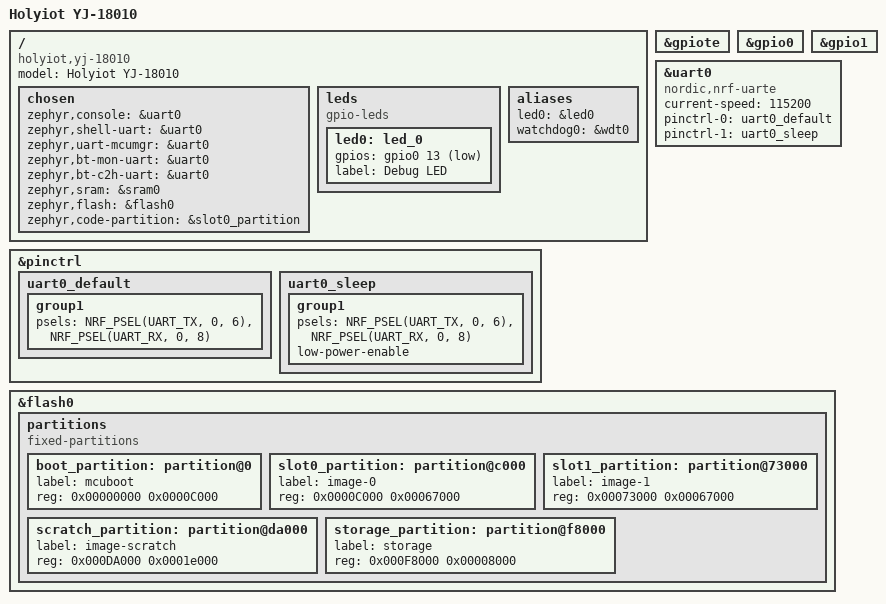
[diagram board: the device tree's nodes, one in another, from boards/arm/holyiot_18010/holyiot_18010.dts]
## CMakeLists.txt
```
# SPDX-License-Identifier: Apache-2.0
# Google FMDN Tracker Firmware (v3 - Dynamic EID)

cmake_minimum_required(VERSION 3.20.0)

# Add custom board definitions
list(APPEND BOARD_ROOT ${CMAKE_CURRENT_SOURCE_DIR})

find_package(Zephyr REQUIRED HINTS $ENV{ZEPHYR_BASE})

project(google_fmdn_tracker)

# Application sources
target_sources(app PRIVATE
    src/main.c
    src/eid_crypto.c
    src/gatt_service.c
)

# tiny-aes-c (AES-256-ECB, ~2 KB flash)
target_sources(app PRIVATE lib/tiny-aes/aes.c)
target_include_directories(app PRIVATE lib/tiny-aes)
target_compile_definitions(app PRIVATE AES256=1)

# micro-ecc (SECP160R1 point multiply, ~4-6 KB flash)
target_sources(app PRIVATE lib/micro-ecc/uECC.c)
target_include_directories(app PRIVATE lib/micro-ecc)
target_compile_definitions(app PRIVATE
    uECC_SUPPORTS_secp160r1=1
    uECC_SUPPORT_COMPRESSED_POINT=0
    uECC_OPTIMIZATION_LEVEL=2
)

target_include_directories(app PRIVATE
    include
    src
)
```

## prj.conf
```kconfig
# Google FMDN Tracker - Dynamic EID (v3)
# Supported: nRF52840, nRF52832
# v3: On-device EID computation + GATT activation window

# ============================================
# Bluetooth - Broadcaster + Peripheral (for GATT)
# ============================================
CONFIG_BT=y
CONFIG_BT_BROADCASTER=y
CONFIG_BT_PERIPHERAL=y

# GATT for activation window
CONFIG_BT_GATT_DYNAMIC_DB=y

# Disable unused features
CONFIG_BT_OBSERVER=n
CONFIG_BT_GATT_CLIENT=n
CONFIG_BT_SETTINGS=n

# ============================================
# Identity management for MAC rotation
# bt_id_reset() changes MAC on each slot rotation
# ============================================
CONFIG_BT_ID_MAX=2

# ============================================
# TX Power - +4 dBm (balanced range/power)
# ============================================
CONFIG_BT_CTLR_TX_PWR_PLUS_4=y

# ============================================
# USB CDC ACM Console (debug build)
# ============================================
CONFIG_SERIAL=y
CONFIG_CONSOLE=y
CONFIG_USB_DEVICE_STACK_NEXT=y
CONFIG_UART_CONSOLE=y
CONFIG_UART_LINE_CTRL=y

# ============================================
# Logging via USB console
# ============================================
CONFIG_LOG=y
CONFIG_LOG_DEFAULT_LEVEL=3
CONFIG_LOG_BACKEND_UART=y
CONFIG_LOG_MODE_DEFERRED=y

# ============================================
# Stack sizes (larger for EC point multiply at boot)
# ============================================
CONFIG_MAIN_STACK_SIZE=4096
CONFIG_SYSTEM_WORKQUEUE_STACK_SIZE=4096
CONFIG_BT_RX_STACK_SIZE=1200

# ============================================
# Size Optimization
# ============================================
CONFIG_SIZE_OPTIMIZATIONS=y
CONFIG_SPEED_OPTIMIZATIONS=n

# ============================================
# Enable MPU Stack Protection
# ============================================
CONFIG_HW_STACK_PROTECTION=y

# ============================================
# LIBC fix for nrf-sdk
# ============================================
CONFIG_MINIMAL_LIBC=y
CONFIG_PICOLIBC=n
```

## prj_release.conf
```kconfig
# Google FMDN Tracker - Ultra Low Power
# Supported: nRF52840, nRF52832
# Version 8: rotation fix (stack + retry + MAC rotation)

# ============================================
# Bluetooth - Minimal Broadcaster
# ============================================
CONFIG_BT=y
CONFIG_BT_BROADCASTER=y

# Disable unused features
CONFIG_BT_PERIPHERAL=n
CONFIG_BT_OBSERVER=n
CONFIG_BT_GATT_CLIENT=n
CONFIG_BT_SETTINGS=n

# ============================================
# Identity management for MAC rotation
# bt_id_reset() changes MAC on each entity rotation
# ============================================
CONFIG_BT_ID_MAX=2

# ============================================
# TX Power - +4 dBm (balanced range/power)
# ============================================
CONFIG_BT_CTLR_TX_PWR_PLUS_4=y

# ============================================
# Disable Serial/UART (saves ~1-5mA)
# ============================================
CONFIG_SERIAL=n
CONFIG_CONSOLE=n
CONFIG_UART_CONSOLE=n

# ============================================
# Disable Logging (saves CPU cycles)
# ============================================
CONFIG_LOG=n
# Note: PRINTK is a dependency of other modules, can't disable

# ============================================
# DC/DC Regulator - already enabled in DTS for nrf52840dk
# (regulator-initial-mode = NRF5X_REG_MODE_DCDC)
# ============================================

# ============================================
# Stack sizes (workqueue needs room for BLE ops during rotation)
# ============================================
CONFIG_MAIN_STACK_SIZE=1024
CONFIG_SYSTEM_WORKQUEUE_STACK_SIZE=2048
CONFIG_BT_RX_STACK_SIZE=1024

# ============================================
# Size Optimization
# ============================================
CONFIG_SIZE_OPTIMIZATIONS=y
CONFIG_SPEED_OPTIMIZATIONS=n

# ============================================
# Enable MPU Stack Protection (detects overflow instead of silent crash)
# ============================================
CONFIG_HW_STACK_PROTECTION=y

# ============================================
# LIBC fix for nrf-sdk
# ============================================
CONFIG_MINIMAL_LIBC=y
CONFIG_PICOLIBC=n
```

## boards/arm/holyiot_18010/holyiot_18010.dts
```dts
/*
 * Holyiot YJ-18010 - nRF52840 Module with Ceramic Antenna
 * Board definition for Zephyr RTOS
 */

/dts-v1/;
#include <nordic/nrf52840_qiaa.dtsi>

/ {
	model = "Holyiot YJ-18010";
	compatible = "holyiot,yj-18010";

	chosen {
		zephyr,console = &uart0;
		zephyr,shell-uart = &uart0;
		zephyr,uart-mcumgr = &uart0;
		zephyr,bt-mon-uart = &uart0;
		zephyr,bt-c2h-uart = &uart0;
		zephyr,sram = &sram0;
		zephyr,flash = &flash0;
		zephyr,code-partition = &slot0_partition;
	};

	/* Optional: LED for debugging (connect external if needed) */
	leds {
		compatible = "gpio-leds";
		led0: led_0 {
			gpios = <&gpio0 13 GPIO_ACTIVE_LOW>;
			label = "Debug LED";
		};
	};

	/* Aliases */
	aliases {
		led0 = &led0;
		watchdog0 = &wdt0;
	};
};

&gpiote {
	status = "okay";
};

&gpio0 {
	status = "okay";
};

&gpio1 {
	status = "okay";
};

/* UART for debugging (optional - can be disabled for production) */
&uart0 {
	compatible = "nordic,nrf-uarte";
	status = "okay";
	current-speed = <115200>;
	pinctrl-0 = <&uart0_default>;
	pinctrl-1 = <&uart0_sleep>;
	pinctrl-names = "default", "sleep";
};

&pinctrl {
	uart0_default: uart0_default {
		group1 {
			psels = <NRF_PSEL(UART_TX, 0, 6)>,
			        <NRF_PSEL(UART_RX, 0, 8)>;
		};
	};

	uart0_sleep: uart0_sleep {
		group1 {
			psels = <NRF_PSEL(UART_TX, 0, 6)>,
			        <NRF_PSEL(UART_RX, 0, 8)>;
			low-power-enable;
		};
	};
};

&flash0 {
	partitions {
		compatible = "fixed-partitions";
		#address-cells = <1>;
		#size-cells = <1>;

		/* Bootloader (optional) */
		boot_partition: partition@0 {
			label = "mcuboot";
			reg = <0x00000000 0x0000C000>;
		};

		/* Application */
		slot0_partition: partition@c000 {
			label = "image-0";
			reg = <0x0000C000 0x00067000>;
		};

		/* OTA slot (optional) */
		slot1_partition: partition@73000 {
			label = "image-1";
			reg = <0x00073000 0x00067000>;
		};

		/* Scratch for OTA */
		scratch_partition: partition@da000 {
			label = "image-scratch";
			reg = <0x000DA000 0x0001e000>;
		};

		/* Storage for NVS */
		storage_partition: partition@f8000 {
			label = "storage";
			reg = <0x000F8000 0x00008000>;
		};
	};
};
```

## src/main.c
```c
/*
 * Google FMDN Tracker - Dynamic EID
 *
 * v3: On-device EID computation from single EIK.
 *
 * Boot sequence:
 * 1. Compute 20 EIDs from EIK (virtual timestamps 0, 1024, ..., 19*1024)
 * 2. First 60s: connectable mode + GATT activation service
 * 3. After 60s: non-connectable FMDN advertising
 * 4. Rotation every ROTATION_PERIOD_SEC: stop adv -> rotate MAC -> next EID -> start adv
 *
 * ADV interval: 2s (more packets in short window)
 * Crypto: tiny-aes-c (AES-256-ECB) + micro-ecc (SECP160R1)
 * Overhead: ~7 KB flash, ~200 B RAM. Boot EID computation: ~3-4 sec.
 */

#include <zephyr/kernel.h>
#include <zephyr/bluetooth/bluetooth.h>
#include <zephyr/sys/util.h>
#include <zephyr/logging/log.h>
#include <string.h>

#include "config.h"
#include "eid_crypto.h"
#include "gatt_service.h"

LOG_MODULE_REGISTER(fmdn, CONFIG_LOG_DEFAULT_LEVEL);

/* Advertising interval: 2000ms (was 5000ms — more packets per rotation window) */
#define ADV_INTERVAL_MIN  3200  /* 2000ms in 0.625ms units */
#define ADV_INTERVAL_MAX  3200

/* FMDN Frame Constants */
#define FMDN_UUID_LOW   0xAA
#define FMDN_UUID_HIGH  0xFE
#define FMDN_FRAME_TYPE 0x41

/* Retry config */
#define ADV_START_MAX_RETRIES 5
#define ADV_START_RETRY_DELAY_MS 50

/* EID pool — computed at boot from EIK */
static uint8_t eid_pool[SLOT_COUNT][EID_LEN];

/* Service Data Structure */
struct __attribute__((packed)) fmdn_service_data {
    uint8_t uuid_low;
    uint8_t uuid_high;
    uint8_t frame_type;
    uint8_t eid[20];
    uint8_t hashed_flags;
};

static struct fmdn_service_data fmdn_data = {
    .uuid_low = FMDN_UUID_LOW,
    .uuid_high = FMDN_UUID_HIGH,
    .frame_type = FMDN_FRAME_TYPE,
    .eid = {0},
    .hashed_flags = 0x80
};

static uint8_t current_slot = 0;

/* Advertising data */
static const struct bt_data ad[] = {
    BT_DATA_BYTES(BT_DATA_FLAGS, BT_LE_AD_GENERAL | BT_LE_AD_NO_BREDR),
    BT_DATA(BT_DATA_SVC_DATA16, &fmdn_data, sizeof(fmdn_data)),
};

/* Non-connectable advertising parameters */
static struct bt_le_adv_param adv_param_nonconn = BT_LE_ADV_PARAM_INIT(
    BT_LE_ADV_OPT_NONE,
    ADV_INTERVAL_MIN,
    ADV_INTERVAL_MAX,
    NULL
);

/* Connectable advertising parameters (for GATT activation window) */
static struct bt_le_adv_param adv_param_conn = BT_LE_ADV_PARAM_INIT(
    BT_LE_ADV_OPT_CONNECTABLE,
    ADV_INTERVAL_MIN,
    ADV_INTERVAL_MAX,
    NULL
);

static bool connectable_mode = true;

/* ---- EID Pool Computation ---- */

static int compute_eid_pool(void)
{
    LOG_INF("Computing %u EIDs from EIK...", SLOT_COUNT);

    for (uint8_t i = 0; i < SLOT_COUNT; i++) {
        /* Virtual timestamp: i * 1024 (each slot = different 1024s window) */
        uint32_t virt_ts = (uint32_t)i * 1024U;
        int rc = generate_eid(TRACKER_EIK, virt_ts, eid_pool[i]);
        if (rc != 0) {
            LOG_ERR("EID computation failed for slot %u", i);
            return -1;
        }
    }

    LOG_INF("EID pool computed. Slot 0: %02x%02x%02x%02x...",
            eid_pool[0][0], eid_pool[0][1],
            eid_pool[0][2], eid_pool[0][3]);
    return 0;
}

/* ---- Advertising ---- */

static void load_slot(uint8_t idx)
{
    if (idx >= SLOT_COUNT) {
        idx = 0;
    }
    memcpy(fmdn_data.eid, eid_pool[idx], EID_LEN);
    current_slot = idx;
    LOG_INF("Slot %u loaded, EID: %02x%02x%02x%02x...", idx,
            fmdn_data.eid[0], fmdn_data.eid[1],
            fmdn_data.eid[2], fmdn_data.eid[3]);
}

static int start_advertising(void)
{
    struct bt_le_adv_param *param = connectable_mode
        ? &adv_param_conn
        : &adv_param_nonconn;
    int err;

    for (int i = 0; i < ADV_START_MAX_RETRIES; i++) {
        k_msleep(ADV_START_RETRY_DELAY_MS);
        err = bt_le_adv_start(param, ad, ARRAY_SIZE(ad), NULL, 0);
        if (err == 0) {
            LOG_INF("Advertising started (%s, attempt %d)",
                    connectable_mode ? "connectable" : "non-connectable",
                    i + 1);
            return 0;
        }
        LOG_WRN("Adv start failed (attempt %d): err %d", i + 1, err);
        k_msleep(ADV_START_RETRY_DELAY_MS * (i + 1));
    }

    LOG_ERR("Advertising failed after %d retries: err %d",
            ADV_START_MAX_RETRIES, err);
    return err;
}

static void rotate_mac_address(void)
{
    int err = bt_id_reset(0, NULL, NULL);
    if (err) {
        LOG_WRN("MAC rotation failed: err %d", err);
    } else {
        LOG_INF("MAC rotated");
    }
}

/* ---- GATT Window Transition ---- */

static void gatt_window_handler(struct k_work *work);
K_WORK_DELAYABLE_DEFINE(gatt_window_work, gatt_window_handler);

static void gatt_window_handler(struct k_work *work)
{
    LOG_INF("=== GATT window closed, switching to non-connectable ===");

    bt_le_adv_stop();
    connectable_mode = false;
    rotate_mac_address();
    start_advertising();
}

/* ---- Slot Rotation ---- */

static void rotation_handler(struct k_work *work);
K_WORK_DELAYABLE_DEFINE(rotation_work, rotation_handler);

static void rotation_handler(struct k_work *work)
{
    uint8_t next = (current_slot + 1) % SLOT_COUNT;

    LOG_INF("=== Rotation %u -> %u ===", current_slot, next);

    bt_le_adv_stop();
    rotate_mac_address();
    load_slot(next);
    start_advertising();

    k_work_schedule(&rotation_work, K_SECONDS(ROTATION_PERIOD_SEC));
}

/* ---- Main ---- */

int main(void)
{
    LOG_INF("FMDN Tracker v3 (dynamic EID) starting...");
    LOG_INF("Slots: %u, rotation: %us, GATT window: %us",
            SLOT_COUNT, ROTATION_PERIOD_SEC, GATT_WINDOW_SEC);

    /* Step 1: Compute EID pool from EIK */
    if (compute_eid_pool() != 0) {
        LOG_ERR("Failed to compute EID pool — halting");
        return 0;
    }

    /* Step 2: Initialize Bluetooth */
    int err = bt_enable(NULL);
    if (err) {
        LOG_ERR("BT init failed: err %d", err);
        return 0;
    }
    LOG_INF("Bluetooth initialized");

    /* Step 3: Initialize GATT activation service */
    gatt_activation_init(TRACKER_SERIAL, eid_pool[0], BOOT_TIMESTAMP);

    /* Step 4: Start connectable advertising (GATT window) */
    connectable_mode = true;
    load_slot(0);
    start_advertising();

    /* Step 5: Schedule GATT window close */
    k_work_schedule(&gatt_window_work, K_SECONDS(GATT_WINDOW_SEC));
    LOG_INF("GATT connectable window: %u seconds", GATT_WINDOW_SEC);

    /* Step 6: Schedule first slot rotation */
    k_work_schedule(&rotation_work, K_SECONDS(ROTATION_PERIOD_SEC));
    LOG_INF("Running. First rotation in %us", ROTATION_PERIOD_SEC);

    return 0;
}
```

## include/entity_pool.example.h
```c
// Example Entity Pool for FMDN Tracker
// This is a PLACEHOLDER - generate real pool using:
//   python3 backend/app/entity_pool.py --size 10 --rotation-hours 6
//
// Then copy the generated entity_pool.h here

#ifndef FMDN_ENTITY_POOL_H
#define FMDN_ENTITY_POOL_H

#include <stdint.h>

// Pool configuration
#define ENTITY_POOL_SIZE 3U
#define ENTITY_ROTATION_HOURS 6U
#define ENTITY_ROTATION_SECONDS (ENTITY_ROTATION_HOURS * 3600U)

// Example EIK pool (32 bytes each) - REPLACE WITH REAL VALUES!
static const uint8_t eik_pool[ENTITY_POOL_SIZE][32] = {
    // Entity 0 - EXAMPLE ONLY
    {
        0x00, 0x11, 0x22, 0x33, 0x44, 0x55, 0x66, 0x77,
        0x88, 0x99, 0xAA, 0xBB, 0xCC, 0xDD, 0xEE, 0xFF,
        0x00, 0x11, 0x22, 0x33, 0x44, 0x55, 0x66, 0x77,
        0x88, 0x99, 0xAA, 0xBB, 0xCC, 0xDD, 0xEE, 0xFF
    },
    // Entity 1 - EXAMPLE ONLY
    {
        0x11, 0x22, 0x33, 0x44, 0x55, 0x66, 0x77, 0x88,
        0x99, 0xAA, 0xBB, 0xCC, 0xDD, 0xEE, 0xFF, 0x00,
        0x11, 0x22, 0x33, 0x44, 0x55, 0x66, 0x77, 0x88,
        0x99, 0xAA, 0xBB, 0xCC, 0xDD, 0xEE, 0xFF, 0x00
    },
    // Entity 2 - EXAMPLE ONLY
    {
        0x22, 0x33, 0x44, 0x55, 0x66, 0x77, 0x88, 0x99,
        0xAA, 0xBB, 0xCC, 0xDD, 0xEE, 0xFF, 0x00, 0x11,
        0x22, 0x33, 0x44, 0x55, 0x66, 0x77, 0x88, 0x99,
        0xAA, 0xBB, 0xCC, 0xDD, 0xEE, 0xFF, 0x00, 0x11
    }
};

// Example Static EID pool (20 bytes each) - REPLACE WITH REAL VALUES!
static const uint8_t eid_pool[ENTITY_POOL_SIZE][20] = {
    // Entity 0 - EXAMPLE ONLY
    {
        0xAA, 0xBB, 0xCC, 0xDD, 0xEE, 0xFF, 0x00, 0x11, 0x22, 0x33,
        0x44, 0x55, 0x66, 0x77, 0x88, 0x99, 0xAA, 0xBB, 0xCC, 0xDD
    },
    // Entity 1 - EXAMPLE ONLY
    {
        0xBB, 0xCC, 0xDD, 0xEE, 0xFF, 0x00, 0x11, 0x22, 0x33, 0x44,
        0x55, 0x66, 0x77, 0x88, 0x99, 0xAA, 0xBB, 0xCC, 0xDD, 0xEE
    },
    // Entity 2 - EXAMPLE ONLY
    {
        0xCC, 0xDD, 0xEE, 0xFF, 0x00, 0x11, 0x22, 0x33, 0x44, 0x55,
        0x66, 0x77, 0x88, 0x99, 0xAA, 0xBB, 0xCC, 0xDD, 0xEE, 0xFF
    }
};

// Hashed flags for each entity
static const uint8_t hashed_flags_pool[ENTITY_POOL_SIZE] = {
    0x80, 0x81, 0x82  // EXAMPLE - UTP mode enabled
};

// Helper function: get current entity index based on uptime
static inline uint8_t get_current_entity_index(uint32_t uptime_seconds) {
    return (uptime_seconds / ENTITY_ROTATION_SECONDS) % ENTITY_POOL_SIZE;
}

#endif // FMDN_ENTITY_POOL_H
```

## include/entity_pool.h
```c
/*
 * Auto-generated Entity Pool for Google52840
 * Generated: 2026-02-13
 * Entities: 20
 * Rotation: 900s (15 min)
 */

#ifndef ENTITY_POOL_H
#define ENTITY_POOL_H

#include <stdint.h>

#define ENTITY_POOL_SIZE 20U
#define ROTATION_PERIOD_SEC 900U

/* Static EID pool - computed at time=0 for each EIK */
static const uint8_t eid_pool[ENTITY_POOL_SIZE][20] = {
    /* Entity 0: entity-0 */
    { 0x30, 0x1C, 0xA4, 0xAF, 0x53, 0xCE, 0x55, 0xB6, 0x76, 0x46, 0xE3, 0x78, 0x89, 0x36, 0xC7, 0x19, 0x4F, 0x7B, 0xCF, 0xFA },

    /* Entity 1: entity-1 */
    { 0x0A, 0xD1, 0x29, 0xC9, 0xF2, 0xC0, 0xED, 0x24, 0x91, 0xB3, 0xDB, 0xA3, 0x84, 0x63, 0x8F, 0x57, 0x7B, 0xAE, 0x93, 0xFA },

    /* Entity 2: entity-2 */
    { 0xF8, 0xD6, 0xCF, 0xE4, 0x0D, 0xFD, 0x1F, 0x91, 0x99, 0xC9, 0xE9, 0x72, 0x03, 0xA8, 0x45, 0x9F, 0x0E, 0xB5, 0xC0, 0x36 },

    /* Entity 3: entity-3 */
    { 0x25, 0x2D, 0xD9, 0xF5, 0xB4, 0xF2, 0x32, 0x18, 0xBE, 0x26, 0xC8, 0x6F, 0x5E, 0x4E, 0xC4, 0x13, 0x8F, 0xD5, 0xA8, 0x51 },

    /* Entity 4: entity-4 */
    { 0x29, 0x5C, 0xF4, 0x4E, 0x0B, 0x06, 0x64, 0xFA, 0x8D, 0xF4, 0xA6, 0x9F, 0xDA, 0x49, 0xB3, 0x7A, 0x51, 0x63, 0x2D, 0x43 },

    /* Entity 5: entity-5 */
    { 0xAE, 0x5D, 0xEA, 0x72, 0xAB, 0x07, 0x03, 0xB7, 0x78, 0xA4, 0x26, 0x5C, 0xC0, 0xA5, 0x08, 0x40, 0x7D, 0x8E, 0x5E, 0x00 },

    /* Entity 6: entity-6 */
    { 0x13, 0xD3, 0x45, 0x70, 0xEB, 0xDD, 0xAE, 0x43, 0xA7, 0xF8, 0x9F, 0x96, 0x61, 0xD9, 0x26, 0x3A, 0x2D, 0x36, 0x16, 0x4C },

    /* Entity 7: entity-7 */
    { 0x8E, 0xAC, 0x47, 0xA7, 0x33, 0x6A, 0x24, 0x41, 0xB5, 0x26, 0xC1, 0x98, 0x8D, 0x04, 0xEB, 0x29, 0xD0, 0xA1, 0x9E, 0x05 },

    /* Entity 8: entity-8 */
    { 0x21, 0x95, 0x0D, 0x87, 0x44, 0x2F, 0xF2, 0x7D, 0xE6, 0x05, 0xE6, 0x34, 0x02, 0x99, 0x6E, 0x6E, 0x1E, 0xC3, 0x1A, 0xB1 },

    /* Entity 9: entity-9 */
    { 0x5E, 0x39, 0x1F, 0xF1, 0x4F, 0xE4, 0x65, 0xA5, 0xC0, 0x8E, 0x74, 0x9D, 0x26, 0x84, 0xEC, 0x62, 0x2E, 0xF3, 0x9C, 0x28 },

    /* Entity 10: entity-10 */
    { 0x22, 0x55, 0x71, 0x24, 0x4D, 0x36, 0x0D, 0x64, 0x19, 0xB3, 0xF2, 0xD1, 0x51, 0x4C, 0x54, 0x27, 0x8E, 0xCC, 0xBE, 0x8B },

    /* Entity 11: entity-11 */
    { 0x86, 0x6B, 0x84, 0x17, 0x10, 0x5A, 0xBA, 0xD8, 0xB0, 0x6A, 0x6C, 0x3E, 0x3A, 0xC4, 0xFF, 0xEC, 0x59, 0x03, 0x89, 0x1D },

    /* Entity 12: entity-12 */
    { 0x7D, 0x2F, 0xDA, 0x2D, 0xFA, 0x98, 0x10, 0x6D, 0x51, 0x60, 0xFE, 0x71, 0xD1, 0xBB, 0xCC, 0x1A, 0xCD, 0xA8, 0xEC, 0xD1 },

    /* Entity 13: entity-13 */
    { 0x29, 0xE0, 0x64, 0x17, 0xAE, 0x6C, 0x37, 0x9E, 0x1C, 0xA8, 0xC9, 0xC7, 0x1A, 0x37, 0xA4, 0xD1, 0x8B, 0x81, 0x16, 0xAE },

    /* Entity 14: entity-14 */
    { 0xF3, 0x16, 0x32, 0xCE, 0x99, 0x30, 0x85, 0x62, 0xF8, 0x63, 0xE3, 0xFA, 0x48, 0xEC, 0xB0, 0x1C, 0x86, 0x10, 0x27, 0xE9 },

    /* Entity 15: entity-15 */
    { 0x4B, 0xC6, 0xD1, 0x2D, 0xD1, 0x80, 0x84, 0x06, 0xA2, 0x9C, 0xE4, 0xF9, 0xFB, 0xB3, 0x58, 0x24, 0x21, 0xE7, 0x75, 0x80 },

    /* Entity 16: entity-16 */
    { 0x3F, 0x4C, 0x14, 0xBE, 0x91, 0x2F, 0x4C, 0x00, 0xE7, 0xFB, 0x24, 0xB1, 0x57, 0x2C, 0xAA, 0xC7, 0x5C, 0xDB, 0x43, 0x4D },

    /* Entity 17: entity-17 */
    { 0x74, 0x08, 0xC6, 0xCD, 0x0F, 0x25, 0xDF, 0xDA, 0x8F, 0x70, 0x1B, 0xD4, 0x1E, 0x0D, 0x10, 0x8B, 0x6D, 0x4C, 0xFA, 0x3D },

    /* Entity 18: entity-18 */
    { 0x95, 0x46, 0xD3, 0x37, 0xE1, 0xA3, 0xE0, 0xC5, 0x0E, 0x27, 0xF0, 0x64, 0x3C, 0x9A, 0xB9, 0x6D, 0x4C, 0x7F, 0xB6, 0x54 },

    /* Entity 19: entity-19 */
    { 0xC1, 0x79, 0xA5, 0x3D, 0x3B, 0x71, 0xB4, 0x3B, 0x0B, 0xA2, 0x21, 0xB8, 0x34, 0x6D, 0xD1, 0x7D, 0xF6, 0x61, 0x56, 0xF0 },

};

/* Hashed flags (0x80 for UTP mode) */
static const uint8_t hashed_flags_pool[ENTITY_POOL_SIZE] = {
    0x80, 0x80, 0x80, 0x80, 0x80, 0x80, 0x80, 0x80, 0x80, 0x80,
    0x80, 0x80, 0x80, 0x80, 0x80, 0x80, 0x80, 0x80, 0x80, 0x80,
};

#endif /* ENTITY_POOL_H */
```

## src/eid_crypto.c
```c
#include "eid_crypto.h"
#include "aes.h"
#include "uECC.h"
#include <string.h>

#define K_EXPONENT 10
#define SECP160R1_ORDER_LEN 21
#define SECP160R1_KEY_LEN   20

/* SECP160R1 curve order (big-endian, 21 bytes)
 * n = 0x0100000000000000000001F4C8F927AED3CA752257 */
static const uint8_t SECP160R1_ORDER[SECP160R1_ORDER_LEN] = {
    0x01, 0x00, 0x00, 0x00, 0x00, 0x00, 0x00, 0x00,
    0x00, 0x00, 0x01, 0xF4, 0xC8, 0xF9, 0x27, 0xAE,
    0xD3, 0xCA, 0x75, 0x22, 0x57
};

/*
 * Big-endian modular reduction: result = num mod modulus
 * Uses bit-by-bit long division (schoolbook method).
 * Only called once per slot at boot — performance irrelevant.
 */
static void bignum_mod(const uint8_t *num, size_t num_len,
                       const uint8_t *mod, size_t mod_len,
                       uint8_t *result, size_t res_len)
{
    uint8_t r[22];
    const size_t r_len = mod_len + 1;
    memset(r, 0, r_len);

    for (size_t bit = 0; bit < num_len * 8; bit++) {
        for (size_t j = 0; j < r_len - 1; j++) {
            r[j] = (r[j] << 1) | (r[j + 1] >> 7);
        }
        r[r_len - 1] <<= 1;

        size_t byte_idx = bit / 8;
        int bit_idx = 7 - (bit % 8);
        if (num[byte_idx] & (1 << bit_idx)) {
            r[r_len - 1] |= 1;
        }

        int ge;
        if (r[0] != 0) {
            ge = 1;
        } else {
            ge = (memcmp(r + 1, mod, mod_len) >= 0) ? 1 : 0;
        }

        if (ge) {
            int borrow = 0;
            for (int j = (int)r_len - 1; j >= 1; j--) {
                int diff = (int)r[j] - (int)mod[j - 1] - borrow;
                if (diff < 0) {
                    diff += 256;
                    borrow = 1;
                } else {
                    borrow = 0;
                }
                r[j] = (uint8_t)diff;
            }
            r[0] = 0;
        }
    }

    memset(result, 0, res_len);
    if (res_len >= mod_len) {
        memcpy(result + res_len - mod_len, r + 1, mod_len);
    } else {
        memcpy(result, r + 1 + (mod_len - res_len), res_len);
    }
}


int generate_eid(const uint8_t eik[EIK_LEN],
                 uint32_t timestamp,
                 uint8_t eid_out[EID_LEN])
{
    /* Step 1: Mask timestamp */
    uint32_t ts_masked = timestamp & ~((1U << K_EXPONENT) - 1);
    uint8_t ts_bytes[4] = {
        (ts_masked >> 24) & 0xFF,
        (ts_masked >> 16) & 0xFF,
        (ts_masked >>  8) & 0xFF,
        (ts_masked      ) & 0xFF
    };

    /* Step 2: Build 32-byte data block */
    uint8_t data[32];
    memset(data, 0xFF, 11);
    data[11] = K_EXPONENT;
    memcpy(data + 12, ts_bytes, 4);
    memset(data + 16, 0x00, 11);
    data[27] = K_EXPONENT;
    memcpy(data + 28, ts_bytes, 4);

    /* Step 3: AES-256-ECB encrypt */
    struct AES_ctx aes_ctx;
    AES_init_ctx(&aes_ctx, eik);
    AES_ECB_encrypt(&aes_ctx, data);
    AES_ECB_encrypt(&aes_ctx, data + 16);

    /* Step 4: r = r' mod SECP160R1.order */
    uint8_t r_scalar[SECP160R1_ORDER_LEN];
    bignum_mod(data, 32,
               SECP160R1_ORDER, SECP160R1_ORDER_LEN,
               r_scalar, SECP160R1_ORDER_LEN);

    /* Step 5: R = r * G */
    uint8_t pubkey[2 * SECP160R1_KEY_LEN];
    if (uECC_compute_public_key(r_scalar, pubkey, uECC_secp160r1()) != 1) {
        return -1;
    }

    /* Step 6: EID = R.x */
    memcpy(eid_out, pubkey, EID_LEN);
    return 0;
}
```

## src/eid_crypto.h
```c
#ifndef EID_CRYPTO_H
#define EID_CRYPTO_H

#include <stdint.h>
#include <stddef.h>

#define EID_LEN       20
#define EIK_LEN       32
#define AES_BLOCK_LEN 32

/**
 * Generate FMDN EID from identity key and timestamp.
 *
 * Algorithm (matches GoogleFindMyTools eid_generator.py):
 * 1. Mask timestamp (zero lower K=10 bits)
 * 2. Build 32-byte data block
 * 3. AES-256-ECB encrypt -> 32-byte r'
 * 4. r = r' mod SECP160R1.order
 * 5. R = r * G (point multiply)
 * 6. EID = R.x (20 bytes, big-endian)
 *
 * @param eik        Identity key (32 bytes)
 * @param timestamp  Unix timestamp (will be masked to 1024s boundary)
 * @param eid_out    Output buffer (20 bytes)
 * @return 0 on success, -1 on error
 */
int generate_eid(const uint8_t eik[EIK_LEN],
                 uint32_t timestamp,
                 uint8_t eid_out[EID_LEN]);

#endif
```

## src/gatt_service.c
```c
/*
 * GATT Activation Service
 *
 * Exposes tracker identity data during the connectable window (first 60s).
 * Mobile app reads these characteristics to activate the tracker on the backend.
 *
 * Service UUID: 0xFEAB (custom, avoids collision with 0xFEAA FMDN)
 * Characteristics:
 *   - tracker_serial  (0x2A00-ish) : 16 bytes, read-only
 *   - current_eid     (0x2A01-ish) : 20 bytes, read-only
 *   - boot_timestamp  (0x2A02-ish) : 4 bytes big-endian, read-only
 */

#include <zephyr/bluetooth/bluetooth.h>
#include <zephyr/bluetooth/gatt.h>
#include <zephyr/bluetooth/uuid.h>
#include <zephyr/logging/log.h>
#include <string.h>

#include "gatt_service.h"
#include "eid_crypto.h"

LOG_MODULE_REGISTER(gatt_act, CONFIG_LOG_DEFAULT_LEVEL);

/* Activation service UUID: 0xFEAB */
#define BT_UUID_ACT_SVC    BT_UUID_DECLARE_16(0xFEAB)
#define BT_UUID_ACT_SERIAL BT_UUID_DECLARE_16(0x2B00)
#define BT_UUID_ACT_EID    BT_UUID_DECLARE_16(0x2B01)
#define BT_UUID_ACT_BOOT   BT_UUID_DECLARE_16(0x2B02)

static uint8_t gatt_serial[TRACKER_SERIAL_LEN];
static uint8_t gatt_eid[EID_LEN];
static uint8_t gatt_boot_ts[4];  /* Big-endian */

static ssize_t read_serial(struct bt_conn *conn,
                           const struct bt_gatt_attr *attr,
                           void *buf, uint16_t len, uint16_t offset)
{
    return bt_gatt_attr_read(conn, attr, buf, len, offset,
                             gatt_serial, TRACKER_SERIAL_LEN);
}

static ssize_t read_eid(struct bt_conn *conn,
                        const struct bt_gatt_attr *attr,
                        void *buf, uint16_t len, uint16_t offset)
{
    return bt_gatt_attr_read(conn, attr, buf, len, offset,
                             gatt_eid, EID_LEN);
}

static ssize_t read_boot_ts(struct bt_conn *conn,
                            const struct bt_gatt_attr *attr,
                            void *buf, uint16_t len, uint16_t offset)
{
    return bt_gatt_attr_read(conn, attr, buf, len, offset,
                             gatt_boot_ts, sizeof(gatt_boot_ts));
}

/* GATT service definition */
BT_GATT_SERVICE_DEFINE(act_svc,
    BT_GATT_PRIMARY_SERVICE(BT_UUID_ACT_SVC),
    BT_GATT_CHARACTERISTIC(BT_UUID_ACT_SERIAL,
                           BT_GATT_CHRC_READ,
                           BT_GATT_PERM_READ,
                           read_serial, NULL, NULL),
    BT_GATT_CHARACTERISTIC(BT_UUID_ACT_EID,
                           BT_GATT_CHRC_READ,
                           BT_GATT_PERM_READ,
                           read_eid, NULL, NULL),
    BT_GATT_CHARACTERISTIC(BT_UUID_ACT_BOOT,
                           BT_GATT_CHRC_READ,
                           BT_GATT_PERM_READ,
                           read_boot_ts, NULL, NULL),
);

void gatt_activation_init(const uint8_t serial[TRACKER_SERIAL_LEN],
                          const uint8_t *eid,
                          uint32_t boot_ts)
{
    memcpy(gatt_serial, serial, TRACKER_SERIAL_LEN);
    memcpy(gatt_eid, eid, EID_LEN);

    gatt_boot_ts[0] = (boot_ts >> 24) & 0xFF;
    gatt_boot_ts[1] = (boot_ts >> 16) & 0xFF;
    gatt_boot_ts[2] = (boot_ts >>  8) & 0xFF;
    gatt_boot_ts[3] = (boot_ts      ) & 0xFF;

    LOG_INF("GATT activation service initialized (serial: %02x%02x...%02x%02x)",
            gatt_serial[0], gatt_serial[1],
            gatt_serial[14], gatt_serial[15]);
}
```

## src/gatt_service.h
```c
#ifndef GATT_SERVICE_H
#define GATT_SERVICE_H

#include <stdint.h>

#define TRACKER_SERIAL_LEN 16
#define GATT_WINDOW_SEC    60  /* Connectable window after boot */

/**
 * Initialize the activation GATT service.
 *
 * Registers characteristics:
 * - tracker_serial (read, 16 bytes)
 * - current_eid    (read, 20 bytes)
 * - boot_timestamp (read, 4 bytes, big-endian)
 *
 * @param serial      Tracker serial number (16 bytes)
 * @param eid         Current EID slot 0 (20 bytes)
 * @param boot_ts     Boot timestamp (seconds since epoch)
 */
void gatt_activation_init(const uint8_t serial[TRACKER_SERIAL_LEN],
                          const uint8_t *eid,
                          uint32_t boot_ts);

#endif
```
